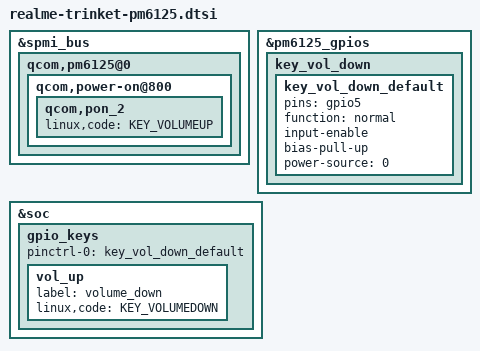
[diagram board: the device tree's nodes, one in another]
#include <dt-bindings/input/qcom,qpnp-power-on.h>
#include <dt-bindings/input/input.h>

&spmi_bus {
	qcom,pm6125@0 {
		qcom,power-on@800 {
			qcom,pon_2 {
				linux,code = <KEY_VOLUMEUP>;
			};
		};
	};
};

&pm6125_gpios {
	key_vol_down {
		key_vol_down_default: key_vol_down_default {
			pins = "gpio5";
			function = "normal";
			input-enable;
			bias-pull-up;
			power-source = <0>;
		};
	};
};

&soc {
	gpio_keys {
		pinctrl-0 = <&key_vol_down_default>;

		vol_up {
			label = "volume_down";
			linux,code = <KEY_VOLUMEDOWN>;
		};
	};
};
